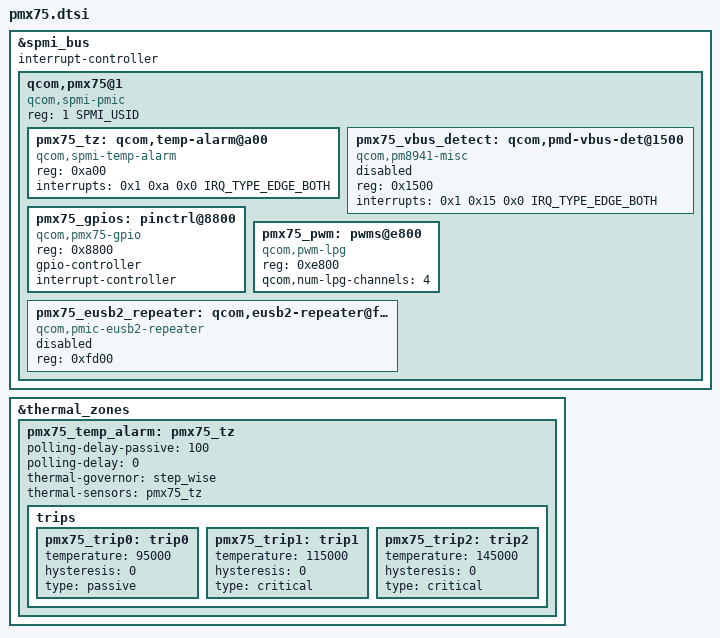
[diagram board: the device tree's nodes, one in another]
#include <dt-bindings/interrupt-controller/irq.h>
#include <dt-bindings/spmi/spmi.h>

&spmi_bus {
	#address-cells = <2>;
	#size-cells = <0>;
	interrupt-controller;
	#interrupt-cells = <4>;

	qcom,pmx75@1 {
		compatible = "qcom,spmi-pmic";
		reg = <1 SPMI_USID>;
		#address-cells = <1>;
		#size-cells = <0>;

		pmx75_tz: qcom,temp-alarm@a00 {
			compatible = "qcom,spmi-temp-alarm";
			reg = <0xa00>;
			interrupts = <0x1 0xa 0x0 IRQ_TYPE_EDGE_BOTH>;
			#thermal-sensor-cells = <0>;
		};

		pmx75_vbus_detect: qcom,pmd-vbus-det@1500 {
			compatible = "qcom,pm8941-misc";
			reg = <0x1500>;
			interrupts = <0x1 0x15 0x0 IRQ_TYPE_EDGE_BOTH>;
			interrupt-names = "usb_vbus";
			status = "disabled";
		};

		pmx75_gpios: pinctrl@8800 {
			compatible = "qcom,pmx75-gpio";
			reg = <0x8800>;
			gpio-controller;
			#gpio-cells = <2>;
			interrupt-controller;
			#interrupt-cells = <2>;
		};

		pmx75_pwm: pwms@e800 {
			compatible = "qcom,pwm-lpg";
			reg = <0xe800>;
			reg-names = "lpg-base";
			#pwm-cells = <2>;
			qcom,num-lpg-channels = <4>;
		};

		pmx75_eusb2_repeater: qcom,eusb2-repeater@fd00 {
			compatible = "qcom,pmic-eusb2-repeater";
			reg = <0xfd00>;
			status = "disabled";
		};
	};
};

&thermal_zones {
	pmx75_temp_alarm: pmx75_tz {
		polling-delay-passive = <100>;
		polling-delay = <0>;
		thermal-governor = "step_wise";
		thermal-sensors = <&pmx75_tz>;

		trips {
			pmx75_trip0: trip0 {
				temperature = <95000>;
				hysteresis = <0>;
				type = "passive";
			};

			pmx75_trip1: trip1 {
				temperature = <115000>;
				hysteresis = <0>;
				type = "critical";
			};

			pmx75_trip2: trip2 {
				temperature = <145000>;
				hysteresis = <0>;
				type = "critical";
			};
		};
	};
};
